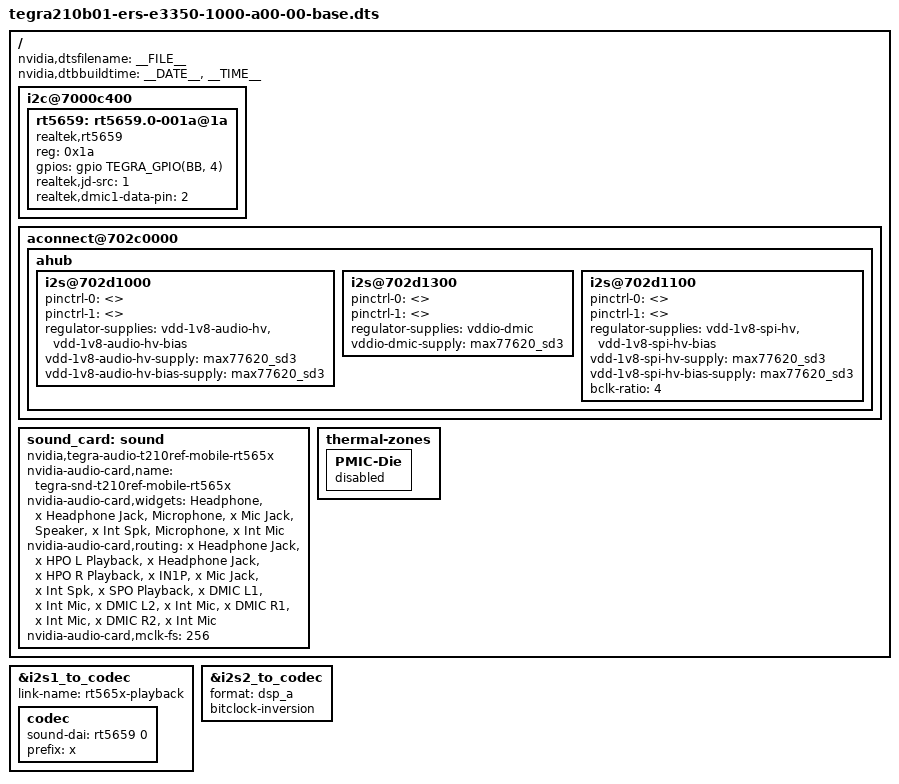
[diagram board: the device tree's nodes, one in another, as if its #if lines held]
/*
 * Copyright (c) 2017, NVIDIA CORPORATION.  All rights reserved.
 *
 * This program is free software; you can redistribute it and/or modify
 * it under the terms of the GNU General Public License as published by
 * the Free Software Foundation; version 2 of the License.
 *
 * This program is distributed in the hope that it will be useful, but WITHOUT
 * ANY WARRANTY; without even the implied warranty of MERCHANTABILITY or
 * FITNESS FOR A PARTICULAR PURPOSE.  See the GNU General Public License for
 * more details.
 *
 * You should have received a copy of the GNU General Public License along
 * with this program; if not, write to the Free Software Foundation, Inc.,
 * 51 Franklin Street, Fifth Floor, Boston, MA  02110-1301, USA.
 */

#include "ers-platforms/tegra210b01-ers-e3350-1000-a00-00-common.dtsi"
#include "ers-platforms/tegra210b01-cvb-e3320-1000-a00.dtsi"
#include "ers-platforms/tegra210b01-ers-power-tree-e2175-1122-a00.dtsi"
#include "ers-platforms/tegra210b01-e3350-1000-a00-padvoltage-default.dtsi"
#include "ers-platforms/tegra210b01-e3350-1000-a00-pinmux.dtsi"
#include "ers-plugin-manager/tegra210b01-ers-plugin-manager.dtsi"

/ {
	nvidia,dtsfilename = __FILE__;
	nvidia,dtbbuildtime = __DATE__, __TIME__;

	i2c@7000c400 {
		rt5659: rt5659.0-001a@1a {
			compatible = "realtek,rt5659";
			reg = <0x1a>;
			gpios = <&gpio TEGRA_GPIO(BB, 4) GPIO_ACTIVE_HIGH>;

			/* refer include/sound/rt5659.h for the values to be used */
			realtek,jd-src = <1>; /* RT5659_JD3 */
			realtek,dmic1-data-pin = <2>; /* RT5659_DMIC1_DATA_GPIO5 */
		};
	};

#if defined(LINUX_VERSION) && LINUX_VERSION >= 409
	aconnect@702c0000 {
#endif
	ahub {
		i2s@702d1000 {
			pinctrl-names = "dap_active", "dap_inactive";
			pinctrl-0 = <>;
			pinctrl-1 = <>;
			regulator-supplies = "vdd-1v8-audio-hv", "vdd-1v8-audio-hv-bias";
			vdd-1v8-audio-hv-supply = <&max77620_sd3>;
			vdd-1v8-audio-hv-bias-supply = <&max77620_sd3>;
		};

		i2s@702d1300 {
			pinctrl-names = "dap_active", "dap_inactive";
			pinctrl-0 = <>;
			pinctrl-1 = <>;
			regulator-supplies = "vddio-dmic";
			vddio-dmic-supply = <&max77620_sd3>;
		};

		i2s@702d1100 {
			pinctrl-names = "dap_active", "dap_inactive";
			pinctrl-0 = <>;
			pinctrl-1 = <>;
			regulator-supplies = "vdd-1v8-spi-hv", "vdd-1v8-spi-hv-bias";
			vdd-1v8-spi-hv-supply = <&max77620_sd3>;
			vdd-1v8-spi-hv-bias-supply = <&max77620_sd3>;
			bclk-ratio = <4>;
		};
	};
#if defined(LINUX_VERSION) && LINUX_VERSION >= 409
	};
#endif

	sound_card: sound {
		compatible = "nvidia,tegra-audio-t210ref-mobile-rt565x";
		nvidia-audio-card,name = "tegra-snd-t210ref-mobile-rt565x";

		nvidia-audio-card,widgets =
			"Headphone",	"x Headphone Jack",
			"Microphone",	"x Mic Jack",
			"Speaker",	"x Int Spk",
			"Microphone",	"x Int Mic";

		nvidia-audio-card,routing =
			"x Headphone Jack",	"x HPO L Playback",
			"x Headphone Jack",	"x HPO R Playback",
			"x IN1P",		"x Mic Jack",
			"x Int Spk",		"x SPO Playback",
			"x DMIC L1",		"x Int Mic",
			"x DMIC L2",		"x Int Mic",
			"x DMIC R1",		"x Int Mic",
			"x DMIC R2",		"x Int Mic";

		nvidia-audio-card,mclk-fs = <256>;
	};

	thermal-zones {
		PMIC-Die {
			status = "disabled";
		};
	};
};

&i2s1_to_codec {
	link-name = "rt565x-playback";

	codec {
		sound-dai = <&rt5659 0>;
		prefix = "x";
	};
};

&i2s2_to_codec {
	format = "dsp_a";
	bitclock-inversion;
};
